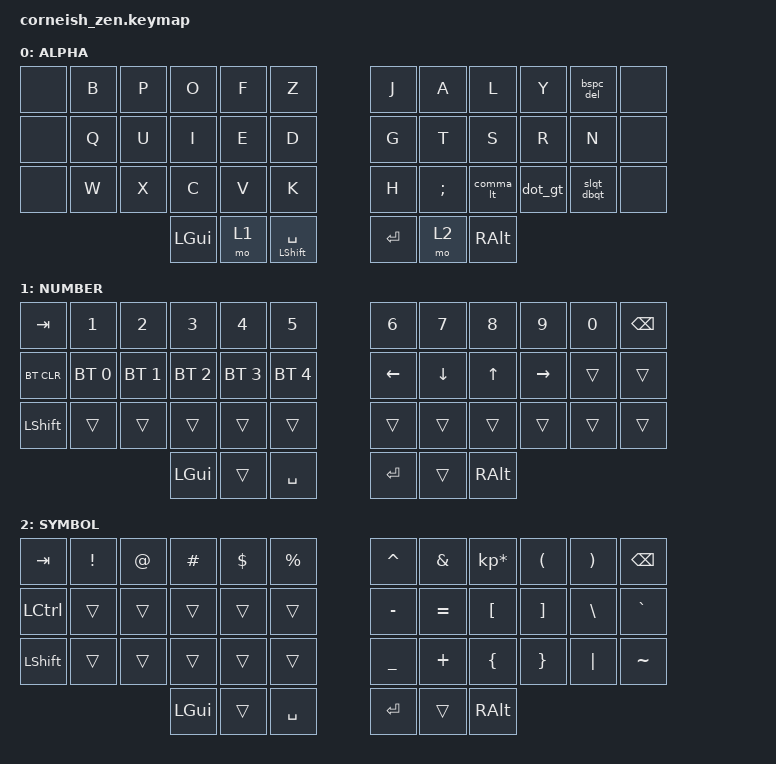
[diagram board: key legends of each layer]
/*
*
* Copyright (c) 2021 Darryl deHaan
* SPDX-License-Identifier: MIT
*
*/

#include <behaviors.dtsi>
#include <dt-bindings/zmk/keys.h>
#include <dt-bindings/zmk/bt.h>

/ {
  chosen {
    zmk,matrix_transform = &default_transform;
    //zmk,matrix_transform = &five_column_transform;
  };
};

/ {
    behaviors {
        /* backspace / delete */
        bspc_del: backspace_delete {
            compatible = "zmk,behavior-mod-morph";
            label = "BACKSPACE_DELETE";
            #binding-cells = <0>;
            bindings = <&kp BACKSPACE>, <&kp DELETE>;
            mods = <(MOD_LSFT|MOD_RSFT)>;
        };
        /* , / < */
        comma_lt: comma_lowerthan {
            compatible = "zmk,behavior-mod-morph";
            label = "COMMA_LOWERTHAN";
            #binding-cells = <0>;
            bindings = <&kp M>, <&kp NUHS>;
            mods = <(MOD_LSFT|MOD_RSFT)>;
        };
        /* . / > */
        dot_gt: dot_greaterthan {
            compatible = "zmk,behavior-mod-morph";
            label = "DOT_GREATERTHAN";
            #binding-cells = <0>;
            bindings = <&kp LS(COMMA)>, <&kp NUHS>;
            mods = <(MOD_LSFT|MOD_RSFT)>;
            keep-mods = <(MOD_LSFT|MOD_RSFT)>;
        };
        /* ' / " */
        slqt_dbqt: singlequote_doublequote {
            compatible = "zmk,behavior-mod-morph";
            label = "SINGLEQUOTE_DOUBLEQUOTE";
            #binding-cells = <0>;
            bindings = <&kp N4>, <&kp N3>;
            mods = <(MOD_LSFT|MOD_RSFT)>;
        };
    };
};


/ {
        keymap {
                compatible = "zmk,keymap";

                default_layer {
                        label = "ALPHA";
// -----------------------------------------------------------------------------------------
// |  TAB |  Q  |  W  |  E  |  R  |  T  |   |  Y  |  U   |  I  |  O  |  P  | BKSP |
// | CTRL |  A  |  S  |  D  |  F  |  G  |   |  H  |  J   |  K  |  L  |  ;  |  '   |
// | SHFT |  Z  |  X  |  C  |  V  |  B  |   |  N  |  M   |  ,  |  .  |  /  | ESC  |
//                    | GUI | LWR | SPC |   | ENT | RSE  | ALT |
//
//
// | XXX  |  B  |  P  |  O  |  F  |  W  |   |  J  |  Q   |  L  |  Y  | BKSP | XXX |
// | XXX  |  A  |  U  |  I  |  E  |  D  |   |  G  |  T   |  S  |  R  |  N   | XXX |
// | XXX  |  Z  |  X  |  C  |  V  |  K  |   |  H  |  M   |  ,< |  .> |  '"  | XXX |
//                    | GUI | LWR | SPC |   | ENT | RSE  | ALT |

                        bindings = <

                        /* row 1 */
                        &none
                        &kp B
                        &kp P
                        &kp O
                        &kp F
                        &kp Z /* W in AZERTY */

                        &kp J
                        &kp A /* Q in AZERTY */
                        &kp L
                        &kp Y
                        &bspc_del /* backspace / delete */
                        &none

                        /* row 2 */
                        &none
                        &kp Q /* A in AZERTY */
                        &kp U
                        &kp I
                        &kp E
                        &kp D

                        &kp G
                        &kp T
                        &kp S
                        &kp R
                        &kp N
                        &none

                        /* row 3 */
                        &none
                        &kp W /* Z in AZERTY */
                        &kp X
                        &kp C
                        &kp V
                        &kp K

                        &kp H
                        &kp SEMI /* M in AZERTY */
                        &comma_lt /* , in AZERTY, TODO < */
                        &dot_gt /* . in AZERTY, TODO > */
                        &slqt_dbqt /* ' in AZERTY */
                        &none

                        /* thumb cluster */
                        &kp LGUI
                        &mo 1 /* hold for "NUMBER" layer */
                        &mt LSHIFT SPACE /* space on tap, shift on hold */

                        &kp RET
                        &mo 2
                        &kp RALT

                        >;
                };
                lower_layer {
                        label = "NUMBER";
// -----------------------------------------------------------------------------------------
// |  TAB |  1  |  2  |  3  |  4  |  5  |   |  6  |  7  |  8  |  9  |  0  | BKSP |
// | BTCLR| BT1 | BT2 | BT3 | BT4 | BT5 |   | LFT | DWN |  UP | RGT |     |      |
// | SHFT |     |     |     |     |     |   |     |     |     |     |     |      |
//                    | GUI |     | SPC |   | ENT |     | ALT |
                        bindings = <
   &kp TAB    &kp N1       &kp N2       &kp N3       &kp N4       &kp N5         &kp N6   &kp N7   &kp N8 &kp N9    &kp N0 &kp BSPC
   &bt BT_CLR &bt BT_SEL 0 &bt BT_SEL 1 &bt BT_SEL 2 &bt BT_SEL 3 &bt BT_SEL 4   &kp LEFT &kp DOWN &kp UP &kp RIGHT &trans &trans
   &kp LSHFT  &trans       &trans       &trans       &trans       &trans         &trans   &trans   &trans &trans    &trans &trans
                          	        &kp LGUI     &trans       &kp SPACE      &kp RET  &trans   &kp RALT
                        >;
                };

                raise_layer {
                        label = "SYMBOL";
// -----------------------------------------------------------------------------------------
// |  TAB |  !  |  @  |  #  |  $  |  %  |   |  ^  |  &  |  *  |  (  |  )  | BKSP |
// | CTRL |     |     |     |     |     |   |  -  |  =  |  [  |  ]  |  \  |  `   |
// | SHFT |     |     |     |     |     |   |  _  |  +  |  {  |  }  | "|" |  ~   |
//                    | GUI |     | SPC |   | ENT |     | ALT |
                        bindings = <
   &kp  TAB  &kp EXCL &kp AT &kp HASH &kp DLLR &kp PRCNT   &kp CARET &kp AMPS  &kp KP_MULTIPLY &kp LPAR &kp RPAR &kp BSPC
   &kp LCTRL &trans   &trans &trans   &trans   &trans      &kp MINUS &kp EQUAL &kp LBKT        &kp RBKT &kp BSLH &kp GRAVE
   &kp LSHFT &trans   &trans &trans   &trans   &trans      &kp UNDER &kp PLUS  &kp LBRC        &kp RBRC &kp PIPE &kp TILDE
                    	     &kp LGUI &trans   &kp SPACE   &kp RET   &trans    &kp RALT
                        >;
                };
        };
};
